# RA register map
Vendor: Renesas; Series: All Chips; File version: x.xx
Registers are 32-bit, read-write, reset 0x0 unless marked. A register's access mark holds for its fields unless they carry their own. Offsets are from the block's base; [hi:lo] are bit positions; {n}, {i} and the like mark numbered series; 'fields as' and 'values as' point back to an identical list; <NAME> marks a mode.

## I3C — I3C Bus Interface
Base 0x40083000
0x00 PRTS reset 0x1 — Protocol Selection Register
  [0] PRTMD — Protocol Mode
    0=I3C protocol mode; 1=I2C protocol mode
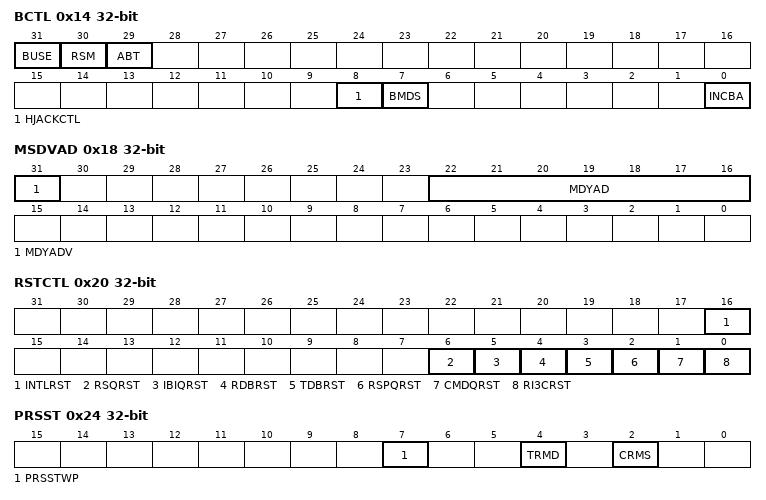
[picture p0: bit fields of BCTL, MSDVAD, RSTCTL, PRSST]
0x14 BCTL — Bus Control Register
  [31] BUSE — Bus Enable
    0=I3C bus operation is disabled; 1=I3C bus operation is enabled
  [30] RSM — Resume
    0=I3C is running; 1=I3C is suspended (RW1C)
  [29] ABT — Abort
    0=I3C is running; 1=I3C has aborted a transfer
  [8] HJACKCTL — Hot-Join Acknowledge Control
    0=ACK the Hot-Join request; 1=NACK and send broadcast CCC to disable Hot-Join
  [7] BMDS — Bus Mode Selection
    0=Legacy inclusive Bus mode disabled; 1=Legacy inclusive (mix) Bus mode enabled
  [0] INCBA — Include I3C Broadcast Address
    0=Do not include I3C broadcast address for private transfers; 1=Include I3C broadcast address for private transfers
0x18 MSDVAD — Master Device Address Register
  [31] MDYADV — Master Dynamic Address Valid
    0=The master dynamic address field is not valid; 1=The master dynamic address field is valid
  [22:16] MDYAD — Master Dynamic Address
0x20 RSTCTL — Reset Control Register
  [16] INTLRST — Internal Software Reset
    0=BITCNT.BCNT[4:0], SVST, BST (not applicable to BST WUCNDDF) registers releases, and Internal releases; 1=BITCNT.BCNT[4:0], SVST, BST (not applicable to BST WUCNDDF) registers resets, and Internal resets
  [6] RSQRST — Receive Status Queue Software Reset
    0=The Receive Status Queue in I3C is not flushed; 1=The Receive Status Queue in I3C is flushed
  [5] IBIQRST — IBI Queue Software Reset
    0=The IBI Queues in I3C is not flushed; 1=The IBI Queues in I3C is flushed
  [4] RDBRST — Receive Data Buffer Software Reset
    0=The Receive Queues in I3C is not flushed; 1=The Receive Queues in I3C is flushed
  [3] TDBRST — Transmit Data Buffer Software Reset
    0=The Transmit Queues in I3C is not flushed; 1=The Transmit Queues in I3C is flushed
  [2] RSPQRST — Response Queue Software Reset
    0=The Response Queues in I3C is not flushed; 1=The Response Queues in I3C is flushed
  [1] CMDQRST — Command Queue Software Reset
    0=The Command Queues in I3C is not flushed; 1=The Command Queues in I3C is flushed
  [0] RI3CRST — I3C Software Reset
    0=Reset of all registers and internal state; 1=Releases of all registers and internal state
0x24 PRSST — Present State Register
  [7] PRSSTWP wo — Present State Write Protect
    0=Bit CRMS are protected; 1=Bit CRMS can be written (When writing simultaneously with the value of the target bit) (This bit is read as 0.)
  [4] TRMD ro — Transmit/Receive Mode
    0=Receive mode; 1=Transmit mode
  [2] CRMS — Current Master
    0=The Master is not the Current Master, and must request and acquire bus ownership before initiating any transfer; 1=The Master is the Current Master, and as a result can initiate transfers
0x30 INST — Internal Status Register
  [10] INEF — Internal Error Flag
    0=I3C Internal Error has not detected; 1=I3C Internal Error has detected
0x34 INSTE — Internal Status Enable Register
  [10] INEE — Internal Error Enable
    0=Disable INST.INEF; 1=Enable INST.INEF
0x38 INIE — Internal Interrupt Enable Register
  [10] INEIE — Internal Error Interrupt Enable
    0=Disables Non-recoverable Internal Error Interrupt Signal; 1=Enables Non-recoverable Internal Error Interrupt Signal
0x3C INSTFC — Internal Status Force Register
  [10] INEFC wo — Internal Error Force
    0=Not force a specific interrupt; 1=Force a specific interrupt
0x44 DVCT ro — Device Characteristic Table Register
  [23:19] IDX — DCT Table Index
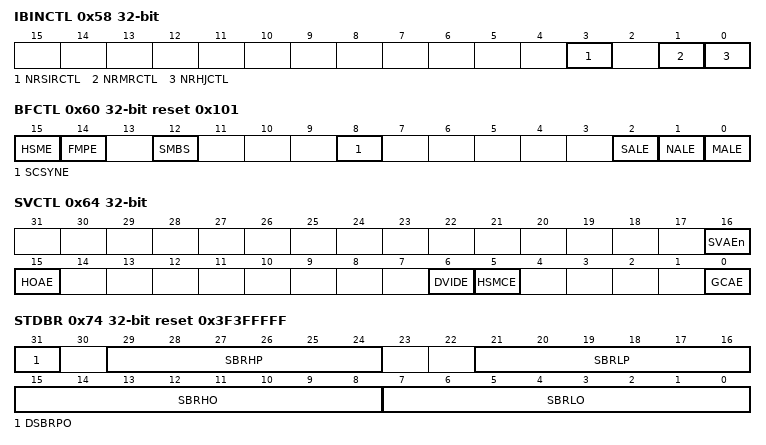
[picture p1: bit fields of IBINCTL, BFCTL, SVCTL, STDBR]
0x58 IBINCTL — IBI Notify Control Register
  [3] NRSIRCTL — Notify Rejected Slave Interrupt Request Control
    0=Do not pass rejected IBI Status to the IBI Queue/Rings, if the incoming SIR is NACKed and is auto-disabled based on DVSIRRJ field in relevant DAT entry; 1=Pass rejected IBI Status to the IBI Queue/Rings, if the incoming SIR is NACKed and is auto-disabled based on DVSIRRJ field in relevant DAT entry
  [1] NRMRCTL — Notify Rejected Master Request Control
    0=Do not pass rejected IBI Status to IBI Queue/Ring, if the incoming Master Request is NACKed and is auto-disabled based on DVMRRJ field in relevant DAT entry; 1=Pass rejected IBI Status to the IBI Queue, if the incoming Master Request is NACKed and is autodisabled based on DVMRRJ field in relevant DAT entry
  [0] NRHJCTL — Notify Rejected Hot-Join Control
    0=Do not pass rejected IBI Status to IBI Queue, if the incoming HotJoin request is NACKed and is autodisabled based on field HJACKCTL of BCTL; 1=Pass rejected IBI Status to the IBI Queue, if the incoming Hot Join request is NACKed and is autodisabled based on field HJACKCTL of BCTL
0x60 BFCTL reset 0x101 — Bus Function Control Register
  [15] HSME — High Speed Mode Enable
    0=Disable High Speed Mode; 1=Enable High Speed Mode
  [14] FMPE — Fast-mode Plus Enable
    0=No Fm+ slope control circuit uses for the SCLn pin and SDAn pin. (n = 0); 1=An Fm+ slope control circuit uses for the SCLn pin and SDAn pin. (n = 0)
  [12] SMBS — SMBus/I2C Bus Selection
    0=The I2C bus select; 1=The SMBus select
  [8] SCSYNE — SCL Synchronous Circuit Enable
    0=No SCL synchronous circuit uses; 1=An SCL synchronous circuit uses
  [2] SALE — Slave Arbitration-Lost Detection Enable
    0=Slave arbitration-lost detection disables; 1=Slave arbitration-lost detection enables
  [1] NALE — NACK Transmission Arbitration-Lost Detection Enable
    0=NACK transmission arbitration-lost detection disables; 1=NACK transmission arbitration-lost detection enables
  [0] MALE — Master Arbitration-Lost Detection Enable
    0=Master arbitration-lost detection disables. (Disables the arbitration-lost detection function and does not clear the CRMS and TRMD bits in PRSST automatically when arbitration is lost.); 1=Master arbitration-lost detection enables. (Enables the arbitration-lost detection function and clears the CRMS and TRMD bits in PRSST automatically when arbitration is lost.)
0x64 SVCTL — Slave Control Register
  [16] SVAEn — Slave Address Enable n (n = 0)
    0=Slave n disables; 1=Slave n enables
  [15] HOAE — Host Address Enable
    0=Host address detection disables; 1=Host address detection enables
  [6] DVIDE — Device-ID Address Enable
    0=Device-ID address detection disables; 1=Device-ID address detection enables
  [5] HSMCE — Hs-mode Master Code Enable
    0=Hs-mode Master Code Detection disables; 1=Hs-mode Master Code Detection enables
  [0] GCAE — General Call Address Enable
    0=General call address detection disables; 1=General call address detection enables
0x70 REFCKCTL — Reference Clock Control Register
  [2:0] IREFCKS — Internal Reference Clock Selection
    0=PCLKD/1 clock; 1=PCLKD/2 clock; 2=PCLKD/4 clock; 3=PCLKD/8 clock; 4=PCLKD/16 clock; 5=PCLKD/32 clock; 6=PCLKD/64 clock; 7=PCLKD/128 clock
0x74 STDBR reset 0x3F3FFFFF — Standard Bit Rate Register
  [31] DSBRPO — Double the Standard Bit Rate Period for Open-Drain
    0=The time period set for SBRHO[7:0] and SBRLO[7:0] is not doubled; 1=The time period set for SBRHO[7:0] and SBRLO[7:0] is doubled
  [29:24] SBRHP — Standard Bit Rate High-Level Period Push-Pull
  [21:16] SBRLP — Standard Bit Rate Low-level Period Push-Pull
  [15:8] SBRHO — Count value of the High-level period of SCL clock
  [7:0] SBRLO — Count value of the Low-level period of SCL clock
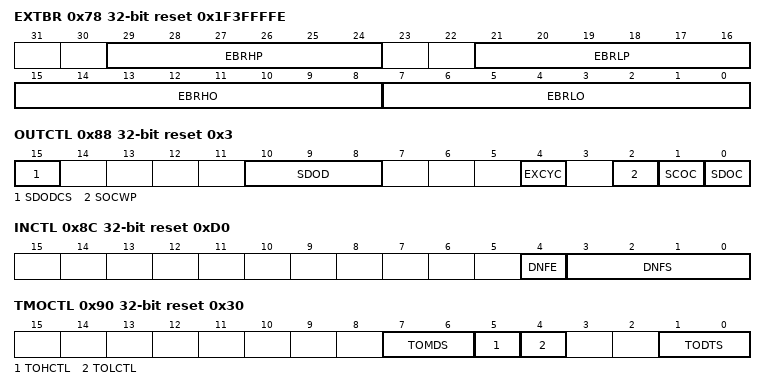
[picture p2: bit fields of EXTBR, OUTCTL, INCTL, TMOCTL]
0x78 EXTBR reset 0x1F3FFFFE — Extended Bit Rate Register
  [29:24] EBRHP — Extended Bit Rate Low-Level Period Push-Pull
  [21:16] EBRLP — Extended Bit Rate Low-Level Period Push-Pull
  [15:8] EBRHO — Extended Bit Rate High-Level Period Open-Drain
  [7:0] EBRLO — Extended Bit Rate Low-Level Period Open-Drain
0x7C BFRECDT — Bus Free Condition Detection Time Register
  [8:0] FRECYC — Bus Free Condition Detection Cycle
0x80 BAVLCDT — Bus Available Condition Detection Time Register
  [8:0] AVLCYC — Bus Available Condition Detection Cycle
0x84 BIDLCDT — Bus Idle Condition Detection Time Register
  [17:0] IDLCYC — Bus Idle Condition Detection Cycle
0x88 OUTCTL reset 0x3 — Output Control Register
  [15] SDODCS — SDA Output Delay Clock Source Selection
    0=The internal reference clock (I3Cφ) is selected as the clock source of the SDA output delay counter; 1=The internal reference clock divided by 2 (I3Cφ/2) is selected as the clock source of the SDA output delay counter
  [10:8] SDOD — SDA Output Delay
    0=No output delay; 1=1 I3Cφ cycle (When OUTCTL.SDODCS = 0 (I3Cφ)) 1 or 2 I3Cφ cycles (When OUTCTL.SDODCS = 1 (I3Cφ/2)); 2=2 I3Cφ cycles (When OUTCTL.SDODCS = 0 (I3Cφ)) 3 or 4 I3Cφ cycles (When OUTCTL.SDODCS = 1 (I3Cφ/2)); 3=3 I3Cφ cycles (When OUTCTL.SDODCS = 0 (I3Cφ)) 5 or 6 I3Cφ cycles (When OUTCTL.SDODCS = 1 (I3Cφ/2)); 4=4 I3Cφ cycles (When OUTCTL.SDODCS = 0 (I3Cφ)) 7 or 8 I3Cφ cycles (When OUTCTL.SDODCS = 1 (I3Cφ/2)); 5=5 I3Cφ cycles (When OUTCTL.SDODCS = 0 (I3Cφ)) 9 or 10 I3Cφ cycles (When OUTCTL.SDODCS = 1 (I3Cφ/2)); 6=6 I3Cφ cycles (When OUTCTL.SDODCS = 0 (I3Cφ)) 11 or 12 I3Cφ cycles (When OUTCTL.SDODCS = 1 (I3Cφ/2)); 7=7 I3Cφ cycles (When OUTCTL.SDODCS = 0 (I3Cφ)) 13 or 14 I3Cφ cycles (When OUTCTL.SDODCS = 1 (I3Cφ/2))
  [4] EXCYC — Extra SCL Clock Cycle Output
    0=Does not output an extra SCL clock cycle (default); 1=Outputs an extra SCL clock cycle
  [2] SOCWP wo — SCL/SDA Output Control Write Protect
    0=Bits SCOC and SDOC are protected; 1=Bits SCOC and SDOC can be written (When writing simultaneously with the value of the target bit). This bit is read as 0.
  [1] SCOC — SCL Output Control
    0=I3C drives the SCLn pin low; 1=I3C releases the SCLn pin
  [0] SDOC — SDA Output Control
    0=I3C drives the SDAn pin low; 1=I3C releases the SDAn pin
0x8C INCTL reset 0xD0 — Input Control Register
  [4] DNFE — Digital Noise Filter Circuit Enable
    0=No digital noise filter circuit is used; 1=A digital noise filter circuit is used
  [3:0] DNFS — Digital Noise Filter Stage Selection
0x90 TMOCTL reset 0x30 — Timeout Control Register
  [7:6] TOMDS — Timeout Operation Mode Selection
    0=Timeout is detected during the following conditions: The bus is busy (BCST.BFREF = 0) in master mode.I3C’s own slave address is detected and the bus is busy in slave mode.The bus is free (BCST.BFREF = 1) while generation of a START condition is requested (CNDCTL.STCND = 1); 1=Timeout is detected while the bus is busy; 2=Timeout is detected while the bus is free; 3=Setting prohibited
  [5] TOHCTL — Timeout H Count Control
    0=Count is disabled while the SCLn line is at a high level; 1=Count is enabled while the SCLn line is at a high level
  [4] TOLCTL — Timeout L Count Control
    0=Count is disabled while the SCLn line is at a low level; 1=Count is enabled while the SCLn line is at a low level
  [1:0] TODTS — Timeout Detection Time Selection
    0=16bit-timeout; 1=14bit-timeout; 2=8bit-timeout; 3=6bit-timeout
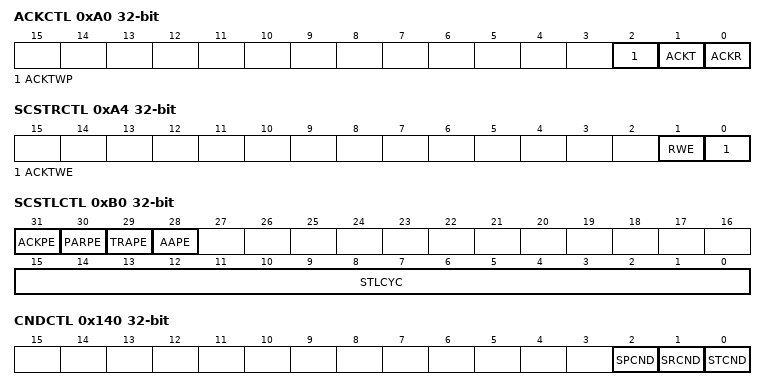
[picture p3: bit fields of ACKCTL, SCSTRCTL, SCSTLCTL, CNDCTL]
0xA0 ACKCTL — Acknowledge Control Register
  [2] ACKTWP wo — ACKT Write Protect
    0=The ACKT bit are protected; 1=The ACKT bit can be written (when writing simultaneously with the value of the target bit). This bit is read as 0.
  [1] ACKT — Acknowledge Transmission
    0=A 0 is sent as the acknowledge bit (ACK transmission); 1=A 1 is sent as the acknowledge bit (NACK transmission)
  [0] ACKR ro — Acknowledge Reception
    0=A 0 is received as the acknowledge bit (ACK reception); 1=A 1 is received as the acknowledge bit (NACK reception)
0xA4 SCSTRCTL — SCL Stretch Control Register
  [1] RWE — Receive Wait Enable
    0=No WAIT (The period between ninth clock cycle and first clock cycle is not held low.); 1=WAIT (The period between ninth clock cycle and first clock cycle is held low.) Low-hold is released by reading NTDTBPn (n = 0)
  [0] ACKTWE — Acknowledge Transmission Wait Enable
    0=NTST.RDBFF0 is set at the rising edge of the ninth SCL clock cycle. (The SCLn line is not held low at the falling edge of the eighth clock cycle.); 1=NTST.RDBFF0 is set at the rising edge of the eighth SCL clock cycle. (The SCLn line is held low at the falling edge of the eighth clock cycle.) Low-hold is released by writing a value to the ACKCTL.ACKT bit.
0xB0 SCSTLCTL — SCL Stalling Control Register
  [31] ACKPE — ACK phase Enable
    0=Does not stall the SCL clock during the ACK/NACK phase; 1=Stall the SCL clock during the ACK/NACK phase
  [30] PARPE — Parity Phase Enable
    0=Does not stall the SCL clock during the parity bit period; 1=Stall the SCL clock during the parity bit period
  [29] TRAPE — Transition Phase Enable
    0=Does not stall the SCL clock during the transition bit in read transfer; 1=Stall the SCL clock during the transition bit in read transfer
  [28] AAPE — Assigend Address Phase Enable
    0=Does not stall the SCL clock during the address assignment phase; 1=Stall the SCL clock during address assignment phase
  [15:0] STLCYC — Stalling Cycle
0xC0 SVTDLG0 — Slave Transfer Data Length Register 0
  [31:16] STDLG — Slave Transfer Data Length
0x140 CNDCTL — Condition Control Register
  [2] SPCND — STOP (P) Condition Issuance
    0=Does not request to issue a STOP condition; 1=Requests to issue a STOP condition
  [1] SRCND — Repeated START (Sr) Condition Issuance
    0=Does not request to issue a Repeated START condition; 1=Requests to issue a Repeated START condition
  [0] STCND — START (S) Condition Issuance
    0=Does not request to issue a START condition; 1=Requests to issue a START condition
0x150 NCMDQP wo — Normal Command Queue Port Register
0x154 NRSPQP ro — Normal Response Queue Port Register
0x158 NTDTBP0 — Normal Transfer Data Buffer Port Register 0
0x17C NIBIQP — Normal IBI Queue Port Register
0x180 NRSQP ro — Normal Receive Status Queue Port Register
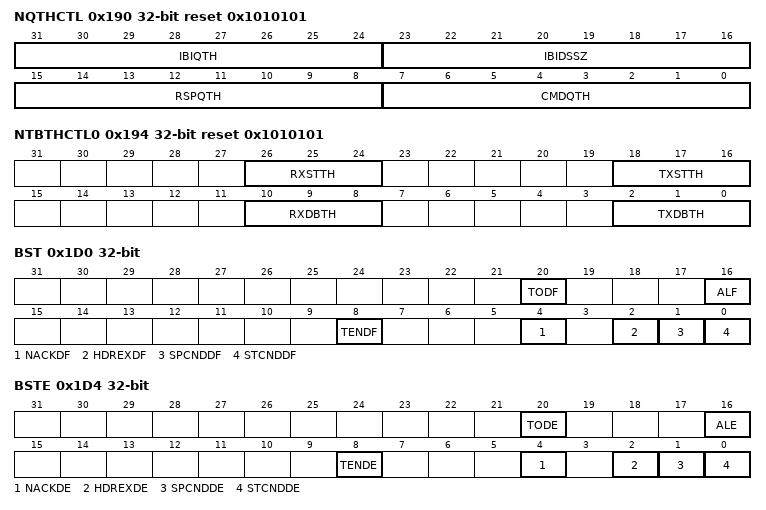
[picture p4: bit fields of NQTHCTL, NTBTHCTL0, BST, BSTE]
0x190 NQTHCTL reset 0x1010101 — Normal Queue Threshold Control Register
  [31:24] IBIQTH — Normal IBI Queue Threshold
    0=I3C Protocol mode (Master): Interrupt is generated when the Outstanding IBI Status count is >= 1. I3C Protocol mode (Slave): Interrupt is issued when IBI Data Buffer is completely empty.; other=Others (I3C Protocol mode (Master): Interrupt is generated when the Outstanding IBI Status is >= N + 1. (N = CMDQTH[7:0]) I3C Protocol mode (Slave): Interrupt is issued when IBI Data Buffer contains N empties.)
  [23:16] IBIDSSZ — Normal IBI Data Segment Size
  [15:8] RSPQTH — Normal Response Queue Threshold
    0=Interrupt is issued when Response Queue contains 1 entry (DWORD); other=Others (Interrupt is triggered when Response Queue contains N+1 entries (DWORD). (N = CMDQTH[7:0]))
  [7:0] CMDQTH — Normal Command Ready Queue Threshold
    0=Interrupt is issued when Command Queue is completely empty; other=Others (Interrupt is issued when Command Queue contains N empties. (N = CMDQTH[7:0]))
0x194 NTBTHCTL0 reset 0x1010101 — Normal Transfer Data Buffer Threshold Control Register 0
  [26:24] RXSTTH — Normal Rx Start Threshold
    0=Wait for 2 empty DWORDs; 1=Wait for 4 empty DWORDs; 2=Wait for 8 empty DWORDs; 3=Wait for 16 empty DWORDs; 4=Wait for 32 empty DWORDs; 5=Wait for 64 empty DWORDs; 6=Wait for 128 empty DWORDs; 7=Wait for 256 empty DWORDs
  [18:16] TXSTTH — Normal Tx Start Threshold
    0=Wait for 2 DWORDs; 1=Wait for 4 DWORDs; 2=Wait for 8 DWORDs; 3=Wait for 16 DWORDs; 4=Wait for 32 DWORDs; 5=Wait for 64 DWORDs; 6=Wait for 128 DWORDs; 7=Wait for 256 DWORDs
  [10:8] RXDBTH — Normal Receive Data Buffer Threshold
    0=Interrupt triggers at 2 Rx Buffer entries, DWORDs; 1=Interrupt triggers at 4 Rx Buffer entries, DWORDs; 2=Interrupt triggers at 8 Rx Buffer entries, DWORDs; 3=Interrupt triggers at 16 Rx Buffer entries, DWORDs; 4=Interrupt triggers at 32 Rx Buffer entries, DWORDs; 5=Interrupt triggers at 64 Rx Buffer entries, DWORDs; 6=Interrupt triggers at 128 Rx Buffer entries, DWORDs; 7=Interrupt triggers at 256 Rx Buffer entries, DWORDs
  [2:0] TXDBTH — Normal Transmit Data Buffer Threshold
    0=Interrupt triggers at 2 Tx Buffer empties, DWORDs; 1=Interrupt triggers at 4 Tx Buffer empties, DWORDs; 2=Interrupt triggers at 8 Tx Buffer empties, DWORDs; 3=Interrupt triggers at 16 Tx Buffer empties, DWORDs; 4=Interrupt triggers at 32 Tx Buffer empties, DWORDs; 5=Interrupt triggers at 64 Tx Buffer empties, DWORDs; 6=Interrupt triggers at 128 Tx Buffer empties, DWORDs; 7=Interrupt triggers at 256 Tx Buffer empties, DWORDs
0x1C0 NRQTHCTL reset 0x1 — Normal Receive Status Queue Threshold Control Register
  [7:0] RSQTH — Normal Receive Status Queue Threshold
    0=Interrupt is issued when Receive Status Queue contains 1 entry (DWORD); other=Others (Interrupt is triggered when Receive Status Queue contains N+1 entries (DWORD). (N = RSQTH[7:0]))
0x1D0 BST — Bus Status Register
  [20] TODF — Timeout Detection Flag
    0=Timeout Detection Interrupt does not occur; 1=Timeout Detection Interrupt occurs
  [16] ALF — Arbitration Lost Flag
    0=Arbitration Lost Interrupt does not occur; 1=Arbitration Lost Interrupt occurs
  [8] TENDF — Transmit End Flag
    0=Transmit End Interrupt does not occur; 1=Transmit End Interrupt occurs
  [4] NACKDF — NACK Detection Flag
    0=NACK Detection Interrupt does not occur; 1=NACK Detection Interrupt occurs
  [2] HDREXDF — HDR Exit Pattern Detection Flag
    0=HDR Exit Pattern Detection Interrupt does not occur; 1=HDR Exit Pattern Detection Interrupt occurs
  [1] SPCNDDF — STOP condition Detection Flag
    0=STOP condition Detection Interrupt does not occur; 1=STOP condition Detection Interrupt occurs
  [0] STCNDDF — START condition Detection Flag
    0=START condition Detection Interrupt does not occur; 1=START condition Detection Interrupt occurs
0x1D4 BSTE — Bus Status Enable Register
  [20] TODE — Timeout Detection Enable
    0=Disables Timeout Detection Interrupt Status logging; 1=Enables Timeout Detection Interrupt Status logging
  [16] ALE — Arbitration Lost Enable
    0=Disables Arbitration Lost Interrupt Status logging; 1=Enables Arbitration Lost Interrupt Status logging
  [8] TENDE — Transmit End Enable
    0=Disables Transmit End Interrupt Status logging; 1=Enables Transmit End Interrupt Status logging
  [4] NACKDE — NACK Detection Enable
    0=Disables NACK Detection Interrupt Status logging; 1=Enables NACK Detection Interrupt Status logging
  [2] HDREXDE — HDR Exit Pattern Detection Enable
    0=Disables HDR Exit Pattern Detection Interrupt Status logging; 1=Enables HDR Exit Pattern Detection Interrupt Status logging
  [1] SPCNDDE — STOP condition Detection Enable
    0=Disables STOP condition Detection Interrupt Status logging; 1=Enables STOP condition Detection Interrupt Status logging
  [0] STCNDDE — START condition Detection Enable
    0=Disables START condition Detection Interrupt Status logging; 1=Enables START condition Detection Interrupt Status logging
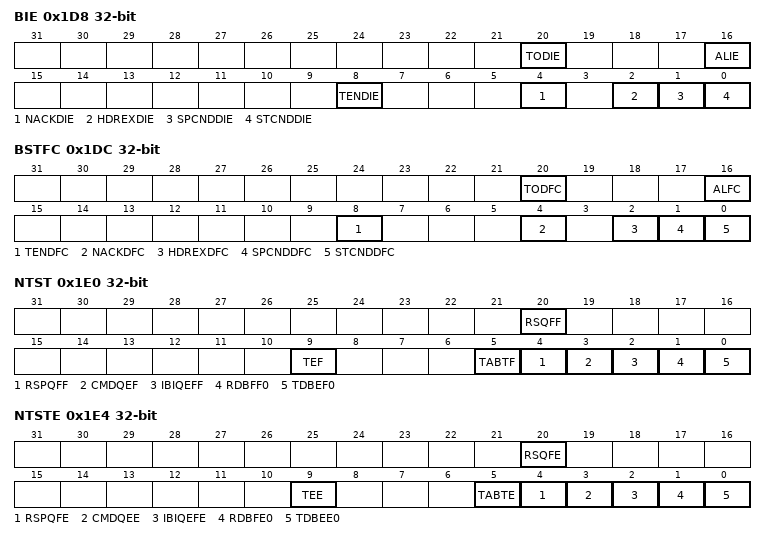
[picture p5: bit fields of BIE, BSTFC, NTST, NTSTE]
0x1D8 BIE — Bus Interrupt Enable Register
  [20] TODIE — Timeout Detection Interrupt Enable
    0=Disables Timeout Detection Interrupt Signal; 1=Enables Timeout Detection Interrupt Signal
  [16] ALIE — Arbitration Lost Interrupt Enable
    0=Disables Arbitration Lost Interrupt Signal; 1=Enables Arbitration Lost Interrupt Signal
  [8] TENDIE — Transmit End Interrupt Enable
    0=Disables Transmit End Interrupt Signal; 1=Enables Transmit End Interrupt Signal
  [4] NACKDIE — NACK Detection Interrupt Enable
    0=Disables NACK Detection Interrupt Signal; 1=Enables NACK Detection Interrupt Signal
  [2] HDREXDIE — HDR Exit Pattern Detection Interrupt Enable
    0=Disables HDR Exit Pattern Detection Interrupt Signal; 1=Enables HDR Exit Pattern Detection Interrupt Signal
  [1] SPCNDDIE — STOP condition Detection Interrupt Enable
    0=Disables STOP condition Detection Interrupt Signal; 1=Enables STOP condition Detection Interrupt Signal
  [0] STCNDDIE — START condition Detection Interrupt Enable
    0=Disables START condition Detection Interrupt Signal; 1=Enables START condition Detection Interrupt Signal
0x1DC BSTFC — Bus Status Force Register
  [20] TODFC wo — Timeout Detection Force
    0=Not Force Timeout Detection Interrupt for software testing; 1=Force Timeout Detection Interrupt for software testing
  [16] ALFC wo — Arbitration Lost Force
    0=Not Force Arbitration Lost Interrupt for software testing; 1=Force Arbitration Lost Interrupt for software testing
  [8] TENDFC wo — Transmit End Force
    0=Not Force Transmit End Interrupt for software testing; 1=Force Transmit End Interrupt for software testing
  [4] NACKDFC wo — NACK Detection Force
    0=Not Force NACK Detection Interrupt for software testing; 1=Force NACK Detection Interrupt for software testing
  [2] HDREXDFC wo — HDR Exit Pattern Detection Force
    0=Not Force HDR Exit Pattern Detection Interrupt for software testing; 1=Force HDR Exit Pattern Detection Interrupt for software testing
  [1] SPCNDDFC wo — STOP condition Detection Force
    0=Not Force STOP condition Detection Interrupt for software testing; 1=Force STOP condition Detection Interrupt for software testing
  [0] STCNDDFC wo — START condition Detection Force
    0=Not Force START condition Detection Interrupt for software testing; 1=Force START condition Detection Interrupt for software testing
0x1E0 NTST — Normal Transfer Status Register
  [20] RSQFF — Normal Receive Status Queue Full Flag
    0=The number of Receive Status Queue entries is <= the NRQTHCTL.RSQTH threshold; 1=The number of Receive Status Queue entries is > the NRQTHCTL.RSQTH threshold
  [9] TEF — Normal Transfer Error Flag
    0=Transfer Error does not occur; 1=Transfer Error occurs. To clear, write 0 to this bit after 1 state is read.
  [5] TABTF — Normal Transfer Abort Flag
    0=Transfer Abort does not occur; 1=Transfer Abort occur. To clear, write 0 to this bit after 1 state is read.
  [4] RSPQFF — Normal Response Queue Full Flag
    0=The number of Response Queue entries is <= the NQTHCTL.RSPQTH threshold; 1=The number of Response Queue entries is > the NQTHCTL.RSPQTH threshold
  [3] CMDQEF — Normal Command Queue Empty Flag
    0=If the NQTHCTL.CMDQTH = 0: The number of Command Queue empties is < the Command Queue size. If the NQTHCTL.CMDQTH is other than 0: The number of Command Queue empties is < the NQTHCTL.CMDQTH threshold.; 1=If the NQTHCTL.CMDQTH = 0: The number of Command Queue empties is the Command Queue size. If the NQTHCTL.CMDQTH is other than 0: 1: The number of Command Queue empties is >= the NQTHCTL.CMDQTH threshold.
  [2] IBIQEFF — Normal IBI Queue Empty/Full Flag
    0=For I3C protocol mode (Master): PRTS.PRTMD bit = 0, PRSST.CRMS bit = 1. The number of IBI Status Queue entries is <= the NQTHCTL.IBIQTH threshold. For I3C protocol mode (Slave) : PRTS.PRTMD bit = 0, PRSST.CRMS bit = 0. If the NQTHCTL.IBIQTH = 0: The number of IBI Data Buffer empties is < the IBI Data Buffer size. If the NQTHCTL.IBIQTH is other than 0: The number of IBI Data Buffer empties is < the NQTHCTL.IBIQTH threshold.; 1=For I3C protocol mode (Master): PRTS.PRTMD bit = 0, PRSST.CRMS bit = 1. The number of IBI Status Queue entries is > the NQTHCTL.IBIQTH threshold. For I3C protocol mode (Slave) : PRTS.PRTMD bit = 0, PRSST.CRMS bit = 0. If the NQTHCTL.IBIQTH = 0: The number of IBI Data Buffer empties is the IBI Data Buffer size. If the NQTHCTL.IBIQTH is other than 0: The number of IBI Data Buffer empties is >= the NQTHCTL.IBIQTH threshold.
  [1] RDBFF0 — Normal Receive Data Buffer Full Flag 0
    0=For I2C protocol mode: PRTS.PRTMD bit = 1. Normal Receive Data Buffer0 contains no receive data. For I3C Protocol mode: PRTS.PRTMD bit = 0. The number of entries in the Normal Receive Data Buffer 0 is < the NTBTHCTL0.RXDBTH[2:0] threshold.; 1=For I2C protocol mode: PRTS.PRTMD bit = 1. Normal Receive Data Buffer0 contains receive data. For I3C Protocol mode: PRTS.PRTMD bit = 0. The number of entries in the Normal Receive Data Buffer 0 is >= the NTBTHCTL0.RXDBTH[2:0] threshold.
  [0] TDBEF0 — Normal Transmit Data Buffer Empty Flag 0
    0=For I2C protocol mode: PRTS.PRTMD bit = 1. Normal Transmit Data Buffer 0 contains transmit data. For I3C protocol mode: PRTS.PRTMD bit = 0. The number of empties in the Normal Transmit Data Buffer 0 is < the NTBTHCTL0.TXDBTH[2:0] threshold.; 1=For I2C protocol mode: PRTS.PRTMD bit = 1. Normal Transmit Data Buffer 0 contains no transmit data. For I3C protocol mode: PRTS.PRTMD bit = 0. The number of empties in the Normal Transmit Data Buffer 0 is >= the NTBTHCTL0.TXDBTH[2:0] threshold.
0x1E4 NTSTE — Normal Transfer Status Enable Register
  [20] RSQFE — Normal Receive Status Queue Full Enable
    0=Disables Receive Status Buffer Full Interrupt Status logging; 1=Enables Receive Status Buffer Full Interrupt Status logging
  [9] TEE — Normal Transfer Error Enable
    0=Disables Transfer Error Interrupt Status logging; 1=Enables Transfer Error Interrupt Status logging
  [5] TABTE — Normal Transfer Abort Enable
    0=Disables Transfer Abort Interrupt Status logging; 1=Enables Transfer Abort Interrupt Status logging
  [4] RSPQFE — Normal Response Queue Full Enable
    0=Disables Response Buffer Full Interrupt Status logging; 1=Enables Response Buffer Full Interrupt Status logging
  [3] CMDQEE — Normal Command Queue Empty Enable
    0=Disables Command Buffer Empty Interrupt Status logging; 1=Enables Command Buffer Empty Interrupt Status logging
  [2] IBIQEFE — Normal IBI Queue Empty/Full Enable
    0=Disables IBI Status Buffer Full Interrupt Status logging; 1=Enables IBI Status Buffer Full Interrupt Status logging
  [1] RDBFE0 — Normal Receive Data Buffer Full Enable 0
    0=Disables Rx0 Data Buffer Full Interrupt Status logging; 1=Enables Rx0 Data Buffer Full Interrupt Status logging
  [0] TDBEE0 — Normal Transmit Data Buffer Empty Enable 0
    0=Disables Tx0 Data Buffer Empty Interrupt Status logging; 1=Enables Tx0 Data Buffer Empty Interrupt Status logging
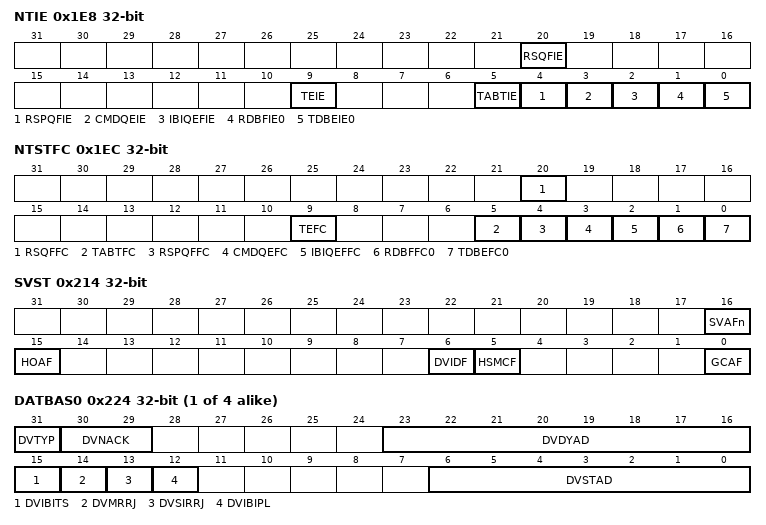
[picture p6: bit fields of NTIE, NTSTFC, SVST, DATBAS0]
0x1E8 NTIE — Normal Transfer Interrupt Enable Register
  [20] RSQFIE — Normal Receive Status Queue Full Interrupt Enable
    0=Disables Receive Status Buffer Full Interrupt Signal; 1=Enables Receive Status Buffer Full Interrupt Signal
  [9] TEIE — Normal Transfer Error Interrupt Enable
    0=Disables Transfer Error Interrupt Signal; 1=Enables Transfer Error Interrupt Signal
  [5] TABTIE — Normal Transfer Abort Interrupt Enable
    0=Disables Transfer Abort Interrupt Signal; 1=Enables Transfer Abort Interrupt Signal
  [4] RSPQFIE — Normal Response Queue Full Interrupt Enable
    0=Disables Response Buffer Full Interrupt Signal; 1=Enables Response Buffer Full Interrupt Signal
  [3] CMDQEIE — Normal Command Queue Empty Interrupt Enable
    0=Disables Command Buffer Empty Interrupt Signal; 1=Enables Command Buffer Empty Interrupt Signal
  [2] IBIQEFIE — Normal IBI Queue Empty/Full Interrupt Enable
    0=Disables IBI Status Buffer Full Interrupt Signal; 1=Enables IBI Status Buffer Full Interrupt Signal
  [1] RDBFIE0 — Normal Receive Data Buffer Full Interrupt Enable 0
    0=Disables Rx0 Data Buffer Full Interrupt Signal; 1=Enables Rx0 Data Buffer Full Interrupt Signal
  [0] TDBEIE0 — Normal Transmit Data Buffer Empty Interrupt Enable 0
    0=Disables Tx0 Data Buffer Empty Interrupt Signal; 1=Enables Tx0 Data Buffer Empty Interrupt Signal
0x1EC NTSTFC — Normal Transfer Status Force Register
  [20] RSQFFC wo — Normal Receive Status Queue Full Force
    0=Not Force Receive Status Buffer Full Interrupt for software testing; 1=Force Receive Status Buffer Full Interrupt for software testing
  [9] TEFC wo — Normal Transfer Error Force
    0=Not Force Transfer Error Interrupt for software testing; 1=Force Transfer Error Interrupt for software testing
  [5] TABTFC wo — Normal Transfer Abort Force
    0=Not Force Transfer Abort Interrupt for software testing; 1=Force Transfer Abort Interrupt for software testing
  [4] RSPQFFC wo — Normal Response Queue Full Force
    0=Not Force Response Buffer Full Interrupt for software testing; 1=Force Response Buffer Full Interrupt for software testing
  [3] CMDQEFC wo — Normal Command Queue Empty Force
    0=Not Force Command Buffer Empty Interrupt for software testing; 1=Force Command Buffer Empty Interrupt for software testing
  [2] IBIQEFFC wo — Normal IBI Queue Empty/Full Force
    0=Not Force IBI Status Buffer Full Interrupt for software testing; 1=Force IBI Status Buffer Full Interrupt for software testing
  [1] RDBFFC0 wo — Normal Receive Data Buffer Full Force 0
    0=Not Force Rx0 Data Buffer Full Interrupt for software testing; 1=Force Rx0 Data Buffer Full Interrupt for software testing
  [0] TDBEFC0 wo — Normal Transmit Data Buffer Empty Force 0
    0=Not Force Tx0 Data Buffer Empty Interrupt for software testing; 1=Force Tx0 Data Buffer Empty Interrupt for software testing
0x214 SVST — Slave Status Register
  [16] SVAFn — Slave Address Detection Flag n (n = 0)
    0=Slave n does not detect; 1=Slave n detect
  [15] HOAF — Host Address Detection Flag
    0=Host address does not detect; 1=Host address detects. This bit set to 1 when the received slave address matches the host address (0001 000).
  [6] DVIDF — Device-ID Address Detection Flag
    0=Device-ID command does not detect; 1=Device-ID command detects. This bit set to 1 when the first frame received immediately after a START condition is detected matches a value of (device ID (1111 100) + 0[W]).
  [5] HSMCF — Hs-mode Master Code Detection Flag
    0=Hs-mode Master Code does not detect; 1=Hs-mode Master Code detects
  [0] GCAF — General Call Address Detection Flag
    0=General call address does not detect; 1=General call address detects
{0x224+8i} DATBAS{i} (i=0..3) — Device Address Table Basic Register {i}
  [31] DVTYP — Device Type
    0=I3C Device; 1=I2C Device
  [30:29] DVNACK — Device NACK Retry Count
  [23:16] DVDYAD — Device I3C Dynamic Address
  [15] DVIBITS — Device IBI Time-stamp
    0=The Master shall not time-stamp IBIs from this Device with Master Time-stamps; 1=The Master shall time-stamp IBIs for this Device with Master Time-stamps
  [14] DVMRRJ — Device In-Band Master Request Reject
    0=This Device shall ACK Master Requests; 1=This Device shall NACK Master Requests and send the auto-disable command
  [13] DVSIRRJ — Device In-Band Slave Interrupt Request Reject
    0=This Device shall ACK the SIR; 1=This Device shall NACK the SIR and send the auto-disable CCC
  [12] DVIBIPL — Device IBI Payload
    0=IBIs from this Device do not carry a Data Payload; 1=IBIs from this Device do carry a Data Payload
  [6:0] DVSTAD — Device Static Address
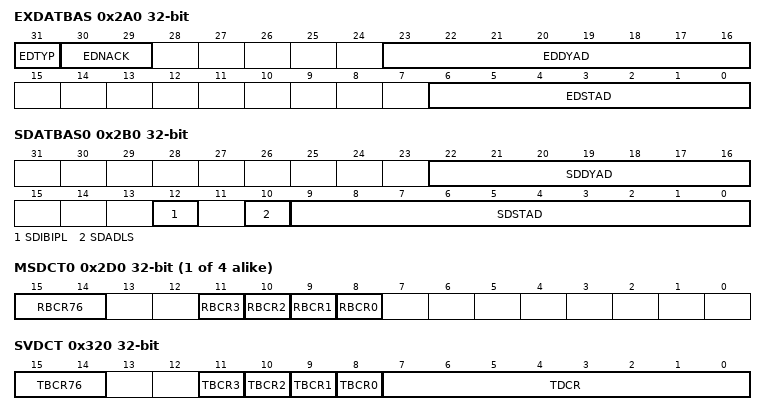
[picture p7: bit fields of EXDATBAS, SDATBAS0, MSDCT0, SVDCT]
0x2A0 EXDATBAS — Extended Device Address Table Basic Register
  [31] EDTYP — Extended Device Type
    0=I3C Device; 1=I2C Device
  [30:29] EDNACK — Extended Device NACK Retry Count
  [23:16] EDDYAD — Extended Device I3C Dynamic Address
  [6:0] EDSTAD — Extended Device Static Address
0x2B0 SDATBAS0 — Slave Device Address Table Basic Register 0 (n = 0)
  [22:16] SDDYAD — Slave Device I3C Dynamic Address
  [12] SDIBIPL — Slave Device IBI Payload
    values as DATBAS0.DVIBIPL
  [10] SDADLS — Slave Device Address Length Selection
    0=Slave Device address length 7 bits selected; 1=Slave Device address length 10 bits selected. (I2C device only)
  [9:0] SDSTAD — Slave Device Static Address
{0x2D0+4i} MSDCT{i} (i=0..3) — Master Device Characteristic Table Register {i}
  [15:14] RBCR76 — Device Role
    0=I3C Slave; 1=I3C Master; 2=Reserved for future definition by MIPI Sensor WG; 3=Reserved for future definition by MIPI Sensor WG
  [11] RBCR3 — Offline Capable
    0=Device will always respond to I3C bus commands; 1=Device will not always respond to I3C bus commands
  [10] RBCR2 — IBI Payload
    0=No data byte follows the accepted IBI; 1=Mandatory one or more data bytes follow the accepted IBI. Data byte continuation is indicated by T-Bit.
  [9] RBCR1 — IBI Request Capable
    0=Not Capable; 1=Capable
  [8] RBCR0 — Max Data Speed Limitation
    0=No Limitation; 1=Limitation
0x320 SVDCT — Slave Device Characteristic Table Register
  [15:14] TBCR76 — Device Role
    values as MSDCT0.RBCR76
  [11] TBCR3 — Offline Capable
    values as MSDCT0.RBCR3
  [10] TBCR2 — IBI Payload
    values as MSDCT0.RBCR2
  [9] TBCR1 — IBI Request Capable
    0=Not Capable; 1=Capable
  [8] TBCR0 — Max Data Speed Limitation
    0=No Limitation; 1=Limitation
  [7:0] TDCR — Transfar Device Characteristic Register
0x324 SDCTPIDL — Slave Device Characteristic Table Provisional ID Low Register
0x328 SDCTPIDH — Slave Device Characteristic Table Provisional ID High Register
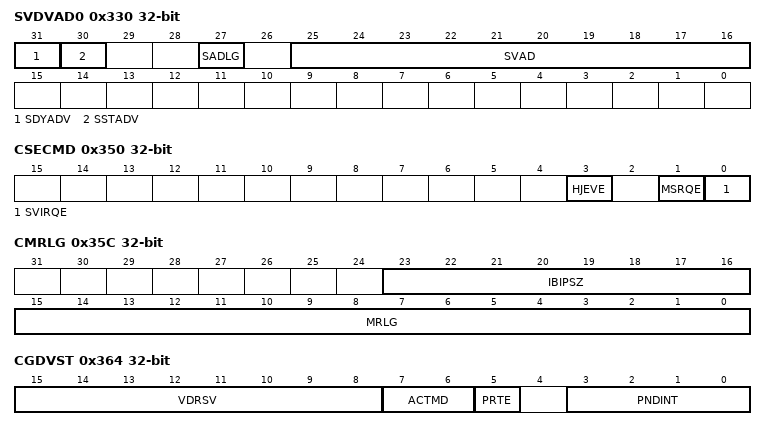
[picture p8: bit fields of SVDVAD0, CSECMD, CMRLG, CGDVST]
{0x330+4i} SVDVAD{i} (i=0..0) ro — Slave Device Address Register {i}
  [31] SDYADV — Slave Dynamic Address Valid
    0=Dynamic Address is disabled; 1=Dynamic Address is enabled
  [30] SSTADV — Slave Static Address Valid
    0=Slave address is disabled; 1=Slave address is enabled
  [27] SADLG — Slave Address Length
    0=The 7-bit address format is selected; 1=The 10-bit address format is selected
  [25:16] SVAD — Slave Address
0x350 CSECMD — CCC Slave Events Command Register
  [3] HJEVE — Hot-Join Event Enable
    0=DISABLED: Slave-initiated Hot-Join is Disabled by the Master to control; 1=ENABLED: Slave-initiated Hot-Join is Enabled by the Master to control
  [1] MSRQE — Mastership Requests Enable
    0=DISABLED: Mastership requests from Secondary Masters is Disabled by the Current Master to control; 1=ENABLED: Mastership requests from Secondary Masters is Enabled by the Current Master to control
  [0] SVIRQE — Slave Interrupt Requests Enable
    0=DISABLED: Slave-initiated Interrupts is Disabled by the Master to control; 1=ENABLED: Slave-initiated Interrupts is Enabled by the Master to control
0x354 CEACTST — CCC Enter Activity State Register
  [3:0] ACTST — Activity State
    1=ENTAS0 (1µs: Latency-free operation); 2=ENTAS1 (100 µs); 4=ENTAS2 (2 ms); 8=ENTAS3 (50 ms: Lowest-activity operation); other=Others (Setting prohibited)
0x358 CMWLG — CCC Max Write Length Register
  [15:0] MWLG — Max Write Length
0x35C CMRLG — CCC Max Read Length Register
  [23:16] IBIPSZ — IBI Payload Size
  [15:0] MRLG — Max Read Length
0x360 CETSTMD ro — CCC Enter Test Mode Register
  [7:0] TSTMD — Test Mode
    0=Exit Test Mode This value removes all I3C devices from Test Mode; 1=Vendor Test Mode This value indicates that I3C devices shall return a random 32bit value in the provisional ID during the Dynamic Address Assignment procedure; other=Others (MIPI reserved Reserved for future use by the MIPI Alliance)
0x364 CGDVST — CCC Get Device Status Register
  [15:8] VDRSV — Vendor Reserved
  [7:6] ACTMD — Slave Device’s current Activity Mode
    {v}=Activity Mode {v} (v=0..3)
  [5] PRTE — Protocol Error
    0=The Slave has not detected a protocol error since the last Status read; 1=The Slave has detected a protocol error since the last Status read
  [3:0] PNDINT — Pending Interrupt
0x368 CMDSPW — CCC Max Data Speed W (Write) Register
  [2:0] MSWDR — Maximum Sustained Write Data Rate
    0=fscl Max (default value); 1=8MHz; 2=6MHz; 3=4MHz; 4=2MHz; other=Others (Setting prohibited)
0x36C CMDSPR — CCC Max Data Speed R (Read) Register
  [2:0] MSRDR — Maximum Sustained Read Data Rate
    0=fscl Max (default value); 1=Setting prohibited; 2=Setting prohibited; 3=4MHz; 4=2MHz; other=Others (Setting prohibited)
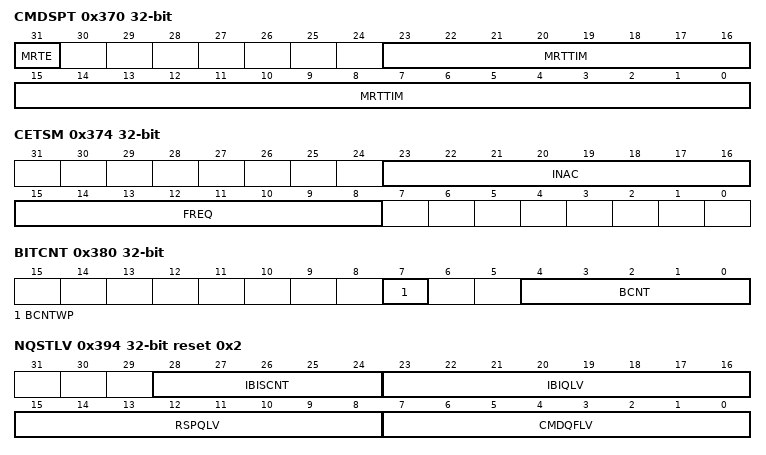
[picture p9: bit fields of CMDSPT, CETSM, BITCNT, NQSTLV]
0x370 CMDSPT — CCC Max Data Speed T (Turnaround) Register
  [31] MRTE — Maximum Read Turnaround Time Enable
    0=Disables transmission of the Maximum Read Turnaround Time. (GETMXDS Format 1: Without Turnaround); 1=Enables transmission of the Maximum Read Turnaround Time. (GETMXDS Format 2: With Turnaround)
  [23:0] MRTTIM — Maximum Read Turnaround Time
0x374 CETSM — CCC Exchange Timing Support Information M (Mode) Register
  [23:16] INAC — Inaccuracy Byte
    0=0.0%; 15=1.5%; 31=3.1%; 47=4.7%; 63=6.3%; 79=7.9%; 95=9.5%; 111=11.1%; 127=12.7%; 143=14.3%; 159=15.9%; 175=17.5%; 191=19.1%; 207=20.7%; 223=22.3%; 239=23.9%; 255=25.5%
  [15:8] FREQ — Frequency Byte
    0=32.0 KHz; 15=7.5 MHz; 31=15.5 MHz; 47=23.5 MHz; 63=31.5 MHz; 79=39.5 MHz; 95=47.5 MHz; 111=55.5 MHz; 127=63.5 MHz; 143=Setting prohibited; 159=Setting prohibited; 175=Setting prohibited; 191=Setting prohibited; 207=Setting prohibited; 223=Setting prohibited; 239=Setting prohibited; 255=Setting prohibited; other=Others (Setting prohibited)
0x380 BITCNT — Bit Count Register
  [7] BCNTWP wo — BCNT Write Protect
    0=The BCNT[4:0] bits are protected; 1=The BCNT[4:0] bits can be written (when writing simultaneously with the value of the target bit). This bit is read as 0.
  [4:0] BCNT — Bit Counter
    0=9 bits (SDR/Legacy I2C Message); 1=1 bit (SDR/Legacy I2C Message); {v}={v} bits (SDR/Legacy I2C Message) (v=2..8); other=Others (setting prohibited)
0x394 NQSTLV ro reset 0x2 — Normal Queue Status Level Register
  [28:24] IBISCNT — Normal IBI Status Count
  [23:16] IBIQLV — Normal IBI Queue Level
  [15:8] RSPQLV — Normal Response Queue Level
  [7:0] CMDQFLV — Normal Command Queue Free Level
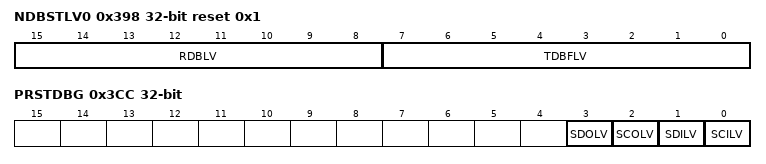
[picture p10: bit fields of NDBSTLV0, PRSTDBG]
0x398 NDBSTLV0 ro reset 0x1 — Normal Data Buffer Status Level Register
  [15:8] RDBLV — Normal Receive Data Buffer Level
  [7:0] TDBFLV — Normal Transmit Data Buffer Free Level
0x3C0 NRSQSTLV ro — Normal Receive Status Queue Status Level Register
  [7:0] RSQLV — Normal Receive Status Queue Level
0x3CC PRSTDBG ro — Present State Debug Register
  [3] SDOLV — SDA Output Level
    0=I3C has driven the SDA pin low; 1=I3C has released the SDA pin
  [2] SCOLV — SCL Output Level
    0=I3C has driven the SCL pin low; 1=I3C has released the SCL pin
  [1] SDILV — SDA Line Signal Level
  [0] SCILV — SCL Line Signal Level
0x3D0 MSERRCNT ro — Master Error Counters Register
  [7:0] M2ECNT — M2 Error Counter
